# ET6801 register map
Vendor: ETMCU Inc.; File version: v0.0.1
CPU: CM7 r2p1, little endian, MPU, FPU, I-cache, D-cache, ITCM, DTCM, 4 interrupt priority bits
Registers are 32-bit, read-write, reset 0x0 unless marked. A register's access mark holds for its fields unless they carry their own. Offsets are from the block's base; [hi:lo] are bit positions; {n}, {i} and the like mark numbered series.

## STIMER0 — Provide an overview of the purpose and functionality of the peripheral: stm_cfg
Base 0x40406000
Same registers: STIMER1 0x40407000, STIMER2 0x40408000, STIMER3 0x40409000, STIMER4 0x4040A000, STIMER5 0x4040B000
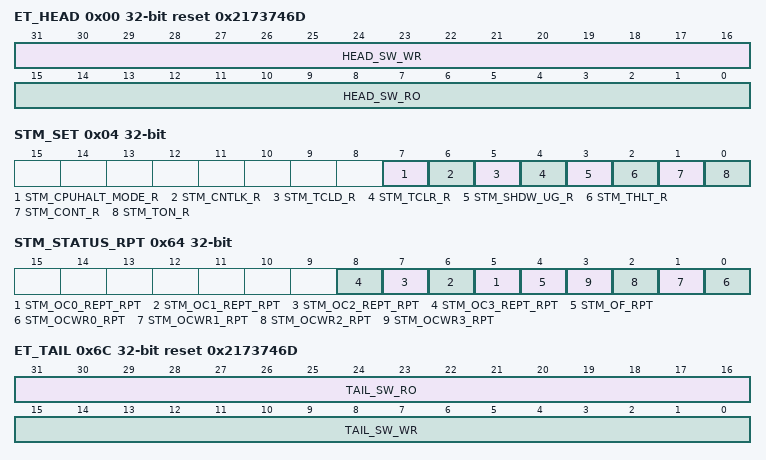
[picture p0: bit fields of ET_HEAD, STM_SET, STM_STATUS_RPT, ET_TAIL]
0x00 ET_HEAD reset 0x2173746D
  [31:16] HEAD_SW_WR — 软件测试读写寄存器，硬件无访问
  [15:0] HEAD_SW_RO ro — 软件只读上报寄存器，硬件无访问，!stm的ASICII 码表示
0x04 STM_SET
  [7] STM_CPUHALT_MODE_R — 软件配置cpu debug模式时，是否需要开启CPU Halt功能，从而暂停计数。 0：开启CPU Halt暂停功能， 1：不开启CPU Halt暂停功能。
  [6] STM_CNTLK_R — 软件配置的锁存脉冲，一个clk_sys时钟周期，当计数器检测到锁存脉冲时，锁定当前值到stm_cnt_rpt寄存器中。
  [5] STM_TCLD_R — 软件周期值立即加载配置 底层逻辑采集其上升沿作为实际加载时刻，如果Timer计数值小于周期值，则直接更新周期值；若Timer计数值大于等于周期值，则Timer立刻清0，并产生OverFlow信号。
  [4] STM_TCLR_R — 软件配置清零功能信号，配置完成后，底层将STimer值清为0。
  [3] STM_SHDW_UG_R — 软件配置周期影子加载模式信号： 当软件配置计数器为影子加载模式时，计数器周期值加载时刻为STM计数到0的时刻进行加载和软件立即加载； 当软件配置计数器为非影子加载模式时，计数器周期值加载时刻只为软件立即加载；
  [2] STM_THLT_R — 软件配置暂停功能信号： 当软件暂停和周期计数OverFlow事件同时来临时，OverFlow事件优先级高，此时STM会翻转计数到0后，再执行暂停操作。并且自动关闭比较门限输出COMP0~3功能，避免暂停在比较门限值处，从而持续输出比较COMP0~3事件和中断。
  [1] STM_CONT_R — 计数器工作模式选择 0：One-Shot模式，则计数到配置周期值后，返回0，并产生一次OverFlow事件； 1：为FreeRUN模式，则为周期自动加载模式，每次计数到配置周期后，返回0并重新计数，同时产生一次OverFlow事件。
  [0] STM_TON_R — 软件配置模块使能信号，控制Timer模块里面所有的寄存器，不使能后该模块输出中断、事件均为0。
0x08 STM_PSCL
  [15:0] STM_PSCL_R — 软件配置时钟源预分频寄存器，分频系数为1~65535，软件需要将其减一后配置，该寄存器为静态配置寄存器，中途不可修改，除非关闭计数器，重新初始化参数。
0x0C TCYC reset 0xFFFFFFFF
  [31:0] STM_TCYC_R — 软件配置周期值寄存器32bit寄存器，配置范围为1~2^32-1，计数到周期值时刻产生OverFlow事件。
0x10 STM_OFWH reset 0xF
  [7:0] STM_OFWH_R — 软件配置OverFlow事件扩展单脉宽参数，将输出OverFlow标志历史告警寄存器信号stm_of_rpt扩展成参数配置值加一的stm_pclk时钟周期宽度。比如说软件配置cfg_stm_ofwh_r为127，则stm_of_exp脉冲宽度为128个stm_pclk时钟周期。 配置的范围是0~255，0是不扩展，255是扩展成256拍。 默认为15，扩展成16拍。
0x14 STM_INT_MASK
  [4:0] STM_INT_MASK — 中断屏蔽信号： cfg_stm_int_mask[4]: 屏蔽来自OVERFLOW事件中断源和中断测试寄存器cfg_stm_int_force_ind[4]的中断信号。 cfg_stm_int_mask[3]: 屏蔽来自ACOMP3中断源和中断测试寄存器cfg_stm_int_force_ind[3]的中断信号。 cfg_stm_int_mask[2]: 屏蔽来自ACOMP2中断源和中断测试寄存器cfg_stm_int_force_ind[2]的中断信号。 cfg_stm_int_mask[1]: 屏蔽来自ACOMP1中断源和中断测试寄存器cfg_stm_int_force_ind[1]的中断信号。 cfg_stm_int_mask[0]: 屏蔽来自ACOMP0中断源和中断测试寄存器cfg_stm_int_force_ind[0]的中断信号。
0x18 STM_INT_EN
  [4:0] STM_INT_EN — 中断源使能信号，配置为高电平时，中断模块才能接收中断源送过来的中断信号。 cfg_stm_int_en[4]: OVERFLOW事件中断源使能信号； cfg_stm_int_en[3]: ACOMP3事件中断源使能信号； cfg_stm_int_en[2]: ACOMP2事件中断源使能信号； cfg_stm_int_en[1]: ACOMP1事件中断源使能信号； cfg_stm_int_en[0]: ACOMP0事件中断源使能信号。
0x1C STM_INT_FORCE_IND
  [4:0] STM_INT_FORCE_IND — 事件中断测试寄存器，自清0寄存器，用于软件中断测试。 cfg_stm_int_force_ind[4]: OVERFLOW事件中断测试寄存器; cfg_stm_int_force_ind[3]: ACOMP3事件中断测试寄存器; cfg_stm_int_force_ind[2]: ACOMP2事件中断测试寄存器; cfg_stm_int_force_ind[1]: ACOMP1事件中断测试寄存器; cfg_stm_int_force_ind[0]: ACOMP0事件中断测试寄存器;
0x20 STM_INT_CLR
  [4:0] STM_INT_CLR — 中断清除寄存器，自清0寄存器，用于清除中断模块里面的中断锁存状态。 cfg_stm_int_clr[4]: OVERFLOW事件中断清除寄存器; cfg_stm_int_clr[3]: ACOMP3事件中断清除寄存器; cfg_stm_int_clr[2]: ACOMP2事件中断清除寄存器; cfg_stm_int_clr[1]: ACOMP1事件中断清除寄存器; cfg_stm_int_clr[0]: ACOMP0事件中断清除寄存器;
{0x24+0xC*i} STM_CPLD{i} (i=0..3)
  [0] STM_CPLD{i}_R — 软件配置立即加载比较器{i}门限信号：在实际加载时刻，如果Timer计数值小于等于比较门限配置，则直接更新比较门限；若Timer计数值大于周期值，则上报告警信号，表明此时配置比较值小于计数值；
0x28 OCWH0
  [31:0] STM_CPNM0_R — 软件配置比较器0 32bit门限寄存器当计数到配置门限值时，产生COMP0比较事件，并可以触发中断，该事件为单脉冲输出。
{0x2C+0xC*i} STM_OCWH{i} reset 0xF (i=0..3)
  [7:0] STM_OCWH{i}_R — 软件配置比较器{i}比较脉冲宽度寄存器，当产生COMP{i}触发比较事件{i}时，比价事件{i}根据cfg_stm_ocwh{i}_r的值，延展脉宽宽度。保证目的模块能采集到脉冲信号。 配置的范围是0~255，0是不扩展，255是扩展成256拍。 默认为15，扩展成16拍。
0x34 OCWH1
  [31:0] STM_CPNM1 — 软件配置比较器1 32bit门限寄存器，当计数到配置门限值时，产生COMP1比较事件，并可以触发中断，该事件为单脉冲输出。
0x40 OCWH2
  [31:0] STM_CPNM2_R — 软件配置比较器2 32bit门限寄存器，当计数到配置门限值时，产生COMP2比较事件，并可以触发中断，该事件为单脉冲输出。
0x4C OCWH3
  [31:0] STM_CPNM3_R — 软件配置比较器3 32bit门限寄存器，当计数到配置门限值时，产生COMP3比较事件，并可以触发中断，该事件为单脉冲输出。
0x54 DMA_HD_MUX
  [2:0] STM_DMA_HMUX — 软件配置DMA握手触发源寄存器： 'd0：选择stm溢出事件作为DMA握手触发信号； 'd1：选择stm比较0事件作为DMA握手触发信号； 'd2：选择stm比较1事件作为DMA握手触发信号； 'd3：选择stm比较2事件作为DMA握手触发信号； 'd4：选择stm比较3事件作为DMA握手触发信号； 'd5~'d7：选择stm溢出事件作为DMA握手触发信号。
0x58 STM_INT_STATUS_RPT ro
  [4:0] STM_INT_STATUS_RPT — stm_int_status_rpt[4]:OVERFLOW中断MASK后中断状态上报； stm_int_status_rpt[3]: ACOMP3中断MASK后中断状态上报； stm_int_status_rpt[2]: ACOMP2中断MASK后中断状态上报； stm_int_status_rpt[1]: ACOMP1中断MASK后中断状态上报； stm_int_status_rpt[0]: ACOMP0中断MASK后中断状态上报。
0x5C STM_INT_RAW_RPT ro
  [4:0] STM_INT_RAW_RPT — stm_int_raw_rpt [4]:OVERFLOW中断MASK前RAW 中断状态上报； stm_int_raw_rpt [3]: ACOMP3中断MASK前RAW 中断状态上报； stm_int_raw_rpt [2]: ACOMP2中断MASK前RAW 中断状态上报； stm_int_raw_rpt [1]: ACOMP1中断MASK前RAW 中断状态上报； stm_int_raw_rpt [0]: ACOMP0中断MASK前RAW 中断状态上报；
0x60 CNT_RPT_LATCH ro
  [31:0] STM_CNT_RPT — 软件可回读当前32bit 计数值。 cfg_stm_cntlk_r为软件配置的锁存脉冲，一个stm_pclk时钟周期，当计数器检测到锁存脉冲时，锁定当前32bit 计数值32bit到stm_cnt_rpt寄存器中。
0x64 STM_STATUS_RPT ro
  [n+5] STM_OC{n}_REPT_RPT read-clears (n=0..3) — COMP{n}比较事件重复脉冲警告寄存器，在比较器脉冲拓展期间，又来了个COMP{n}比较事件脉冲，此时会忽略重复脉冲，并产生重复脉冲告警，
  [4] STM_OF_RPT read-clears — OverFlow标志上报，为历史告警寄存器。
  [n] STM_OCWR{n}_RPT read-clears (n=0..3) — 当软件配置立即加载比较器{n}门限值时，在实际加载时刻，若Timer计数值大于周期值，则上报告警信号，表明此时配置比较值小于计数值。
0x68 CNT_RPT ro
  [31:0] STM_CNT_RPT — 软件可回读当前32bit 计数值。实时上报不锁存；
0x6C ET_TAIL reset 0x2173746D
  [31:16] TAIL_SW_RO ro — 软件只读硬件上报寄存器
  [15:0] TAIL_SW_WR — 软件测试读写寄存器，硬件无访问
